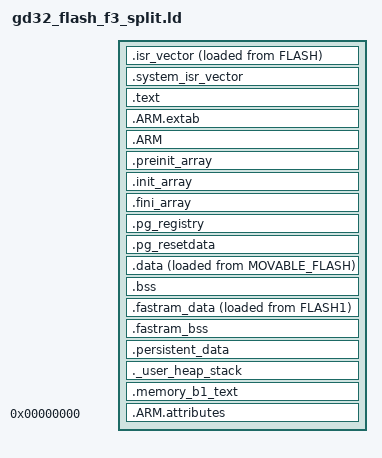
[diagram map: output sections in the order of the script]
/*
*****************************************************************************
**
**  File        : gd32_flash_f3_split.ld
**
**  Abstract    : Common linker script for GD32F30x devices.
**
*****************************************************************************
*/

/* Entry Point */
ENTRY(Reset_Handler)

/* Highest address of the user mode stack */
_Hot_Reboot_Flags_Size = 16;
_estack = ORIGIN(STACKRAM) + LENGTH(STACKRAM) - _Hot_Reboot_Flags_Size;

/* Base address where the config is stored. */
__config_start = ORIGIN(FLASH_CONFIG);
__config_end = ORIGIN(FLASH_CONFIG) + LENGTH(FLASH_CONFIG);

/* Generate a link error if heap and stack don't fit into RAM */
_Min_Heap_Size = 0;
_Min_Stack_Size = 0x800;

SECTIONS
{
  _isr_vector_table_flash_base = LOADADDR(.isr_vector);
  PROVIDE (isr_vector_table_flash_base = _isr_vector_table_flash_base);

  .isr_vector :
  {
    . = ALIGN(4);
    PROVIDE (isr_vector_table_base = .);
    KEEP(*(.isr_vector))
    . = ALIGN(4);
    PROVIDE (isr_vector_table_end = .);
  } >VECTAB AT> FLASH

  .system_isr_vector (NOLOAD) :
  {
    . = ALIGN(4);
    PROVIDE (system_isr_vector_table_base = .);
    KEEP(*(.system_isr_vector))
    . = ALIGN(4);
  } >SYSTEM_MEMORY

  .text :
  {
    . = ALIGN(4);
    *(.text)
    *(.text*)
    *(.rodata)
    *(.rodata*)
    *(.glue_7)
    *(.glue_7t)
    *(.eh_frame)

    KEEP (*(.init))
    KEEP (*(.fini))

    . = ALIGN(4);
    _etext = .;
  } >FLASH1

  .ARM.extab   : { *(.ARM.extab* .gnu.linkonce.armextab.*) } >FLASH
  .ARM : {
    __exidx_start = .;
    *(.ARM.exidx*)
    __exidx_end = .;
  } >MOVABLE_FLASH

  .preinit_array :
  {
    PROVIDE_HIDDEN (__preinit_array_start = .);
    KEEP (*(.preinit_array*))
    PROVIDE_HIDDEN (__preinit_array_end = .);
  } >MOVABLE_FLASH
  .init_array :
  {
    PROVIDE_HIDDEN (__init_array_start = .);
    KEEP (*(SORT(.init_array.*)))
    KEEP (*(.init_array*))
    PROVIDE_HIDDEN (__init_array_end = .);
  } >MOVABLE_FLASH
  .fini_array :
  {
    PROVIDE_HIDDEN (__fini_array_start = .);
    KEEP (*(.fini_array*))
    KEEP (*(SORT(.fini_array.*)))
    PROVIDE_HIDDEN (__fini_array_end = .);
  } >MOVABLE_FLASH
  .pg_registry :
  {
    PROVIDE_HIDDEN (__pg_registry_start = .);
    KEEP (*(.pg_registry))
    KEEP (*(SORT(.pg_registry.*)))
    PROVIDE_HIDDEN (__pg_registry_end = .);
  } >MOVABLE_FLASH
  .pg_resetdata :
  {
    PROVIDE_HIDDEN (__pg_resetdata_start = .);
    KEEP (*(.pg_resetdata))
    PROVIDE_HIDDEN (__pg_resetdata_end = .);
  } >FLASH1

  _sidata = LOADADDR(.data);

  .data :
  {
    . = ALIGN(4);
    _sdata = .;
    *(.data)
    *(.data*)
    . = ALIGN(4);
    _edata = .;
  } >RAM AT> MOVABLE_FLASH

  . = ALIGN(4);
  .bss (NOLOAD) :
  {
    _sbss = .;
    __bss_start__ = _sbss;
    *(.bss)
    *(SORT_BY_ALIGNMENT(.bss*))
    *(COMMON)
    . = ALIGN(4);
    _ebss = .;
    __bss_end__ = _ebss;
  } >RAM

  _sfastram_idata = LOADADDR(.fastram_data);

  .fastram_data :
  {
    . = ALIGN(4);
    _sfastram_data = .;
    *(.fastram_data)
    *(.fastram_data*)
    . = ALIGN(4);
    _efastram_data = .;
  } >FASTRAM AT> FLASH1

  . = ALIGN(4);
  .fastram_bss (NOLOAD) :
  {
    __fastram_bss_start__ = .;
    *(.fastram_bss)
    *(SORT_BY_ALIGNMENT(.fastram_bss*))
    . = ALIGN(4);
    __fastram_bss_end__ = .;
  } >FASTRAM

  .persistent_data (NOLOAD) :
  {
    __persistent_data_start__ = .;
    *(.persistent_data)
    . = ALIGN(4);
    __persistent_data_end__ = .;
  } >RAM

  _heap_stack_end = ORIGIN(STACKRAM) + LENGTH(STACKRAM) - _Hot_Reboot_Flags_Size;
  _heap_stack_begin = _heap_stack_end - _Min_Stack_Size - _Min_Heap_Size;
  . = _heap_stack_begin;
  ._user_heap_stack :
  {
    . = ALIGN(4);
    PROVIDE ( end = . );
    PROVIDE ( _end = . );
    . = . + _Min_Heap_Size;
    . = . + _Min_Stack_Size;
    . = ALIGN(4);
  } >STACKRAM = 0xa5

  .memory_b1_text :
  {
    *(.mb1text)
    *(.mb1text*)
    *(.mb1rodata)
    *(.mb1rodata*)
  } >MEMORY_B1

  /DISCARD/ :
  {
    libc.a ( * )
    libm.a ( * )
    libgcc.a ( * )
  }

  .ARM.attributes 0 : { *(.ARM.attributes) }
}

ASSERT(__persistent_data_end__ <= _heap_stack_begin, "GD32 RAM overlaps reserved stack")
